# ATSAML22G17A device description
Architecture: CORTEX-M0PLUS; Family: SAML; Series: SAML22
Registers are 32-bit, read-write, reset 0x0 unless marked. A register's access mark holds for its fields unless they carry their own. Offsets are from the block's base; [hi:lo] are bit positions; {n}, {i} and the like mark numbered series; 'fields as' and 'values as' point back to an identical list.

## GCLK — Generic Clock Generator
Instances: GCLK 0x40001C00
0x00 CTRLA 8-bit (WSYNC) — Control
  [0] SWRST — Software Reset
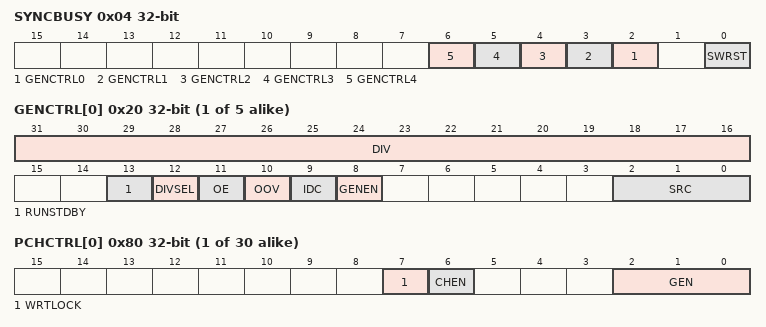
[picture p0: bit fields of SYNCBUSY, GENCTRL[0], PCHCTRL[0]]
0x04 SYNCBUSY ro — Synchronization Busy
  [n+2] GENCTRL{n} (n=0..4) — Generic Clock Generator Control {n} Synchronization Busy bits
    1=GCLK0 (Generic clock generator 0); 2=GCLK1 (Generic clock generator 1); 4=GCLK2 (Generic clock generator 2); 8=GCLK3 (Generic clock generator 3); 16=GCLK4 (Generic clock generator 4)
  [0] SWRST — Software Reset Synchroniation Busy bit
{0x20+4i} GENCTRL[{i}] (i=0..4) — Generic Clock Generator Control
  [31:16] DIV — Division Factor
  [13] RUNSTDBY — Run in Standby
  [12] DIVSEL — Divide Selection
    0=DIV1 (Divide input directly by divider factor); 1=DIV2 (Divide input by 2^(divider factor+ 1))
  [11] OE — Output Enable
  [10] OOV — Output Off Value
  [9] IDC — Improve Duty Cycle
  [8] GENEN — Generic Clock Generator Enable
  [2:0] SRC — Source Select
    0=XOSC (XOSC oscillator output); 1=GCLKIN (Generator input pad); 2=GCLKGEN1 (Generic clock generator 1 output); 3=OSCULP32K (OSCULP32K oscillator output); 4=XOSC32K (XOSC32K oscillator output); 5=OSC16M (OSC16M oscillator output); 6=DFLL48M (DFLL48M output); 7=DPLL96M (DPLL96M output)
{0x80+4i} PCHCTRL[{i}] (i=0..29) — Peripheral Clock Control
  [7] WRTLOCK — Write Lock
  [6] CHEN — Channel Enable
  [2:0] GEN — Generic Clock Generator
    {v}=GCLK{v} (Generic clock generator {v}) (v=0..4)

## MCLK — Main Clock
Instances: MCLK 0x40000800
0x01 INTENCLR 8-bit (atomic clear) — Interrupt Enable Clear
  [0] CKRDY — Clock Ready Interrupt Enable
0x02 INTENSET 8-bit (atomic set) — Interrupt Enable Set
  [0] CKRDY — Clock Ready Interrupt Enable
0x03 INTFLAG 8-bit reset 0x1 (atomic clear) — Interrupt Flag Status and Clear
  [0] CKRDY — Clock Ready
0x04 CPUDIV 8-bit reset 0x1 — CPU Clock Division
  [7:0] CPUDIV — CPU Clock Division Factor
    1=DIV1 (Divide by 1); 2=DIV2 (Divide by 2); 4=DIV4 (Divide by 4); 8=DIV8 (Divide by 8); 16=DIV16 (Divide by 16); 32=DIV32 (Divide by 32); 64=DIV64 (Divide by 64); 128=DIV128 (Divide by 128)
0x06 BUPDIV 8-bit reset 0x1 — Backup Clock Division
  [7:0] BUPDIV — Backup Clock Division Factor
    values as CPUDIV.CPUDIV
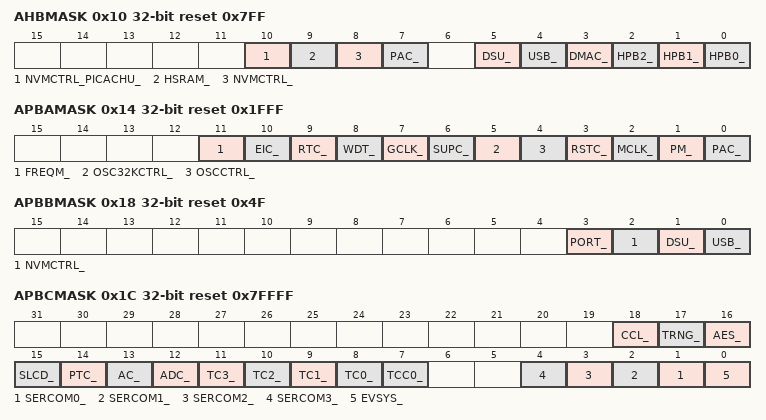
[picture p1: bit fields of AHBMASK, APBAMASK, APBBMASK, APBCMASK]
0x10 AHBMASK reset 0x7FF
  [10] NVMCTRL_PICACHU_ — NVMCTRL_PICACHU AHB Clock Mask
  [9] HSRAM_ — HSRAM AHB Clock Mask
  [8] NVMCTRL_ — NVMCTRL AHB Clock Mask
  [7] PAC_ — PAC AHB Clock Mask
  [5] DSU_ — DSU AHB Clock Mask
  [4] USB_ — USB AHB Clock Mask
  [3] DMAC_ — DMAC AHB Clock Mask
  [2] HPB2_ — HPB2 AHB Clock Mask
  [1] HPB1_ — HPB1 AHB Clock Mask
  [0] HPB0_ — HPB0 AHB Clock Mask
0x14 APBAMASK reset 0x1FFF
  [11] FREQM_ — FREQM APB Clock Enable
  [10] EIC_ — EIC APB Clock Enable
  [9] RTC_ — RTC APB Clock Enable
  [8] WDT_ — WDT APB Clock Enable
  [7] GCLK_ — GCLK APB Clock Enable
  [6] SUPC_ — SUPC APB Clock Enable
  [5] OSC32KCTRL_ — OSC32KCTRL APB Clock Enable
  [4] OSCCTRL_ — OSCCTRL APB Clock Enable
  [3] RSTC_ — RSTC APB Clock Enable
  [2] MCLK_ — MCLK APB Clock Enable
  [1] PM_ — PM APB Clock Enable
  [0] PAC_ — PAC APB Clock Enable
0x18 APBBMASK reset 0x4F
  [3] PORT_ — PORT APB Clock Enable
  [2] NVMCTRL_ — NVMCTRL APB Clock Enable
  [1] DSU_ — DSU APB Clock Enable
  [0] USB_ — USB APB Clock Enable
0x1C APBCMASK reset 0x7FFFF
  [18] CCL_ — CCL APB Clock Enable
  [17] TRNG_ — TRNG APB Clock Enable
  [16] AES_ — AES APB Clock Enable
  [15] SLCD_ — SLCD APB Clock Enable
  [14] PTC_ — PTC APB Clock Enable
  [13] AC_ — AC APB Clock Enable
  [12] ADC_ — ADC APB Clock Enable
  [n+8] TC{n}_ (n=0..3) — TC{n} APB Clock Enable
  [7] TCC0_ — TCC0 APB Clock Enable
  [n+1] SERCOM{n}_ (n=0..3) — SERCOM{n} APB Clock Enable
  [0] EVSYS_ — EVSYS APB Clock Enable

## Notices in the file
Copyright (c) 2018 Microchip Technology Inc.
SPDX-License-Identifier: Apache-2.0
Licensed under the Apache License, Version 2.0 (the "License");
you may not use this file except in compliance with the License.
You may obtain a copy of the License at
http://www.apache.org/licenses/LICENSE-2.0
Unless required by applicable law or agreed to in writing, software
distributed under the License is distributed on an "AS IS" BASIS,
WITHOUT WARRANTIES OR CONDITIONS OF ANY KIND, either express or implied.
See the License for the specific language governing permissions and
limitations under the License.
